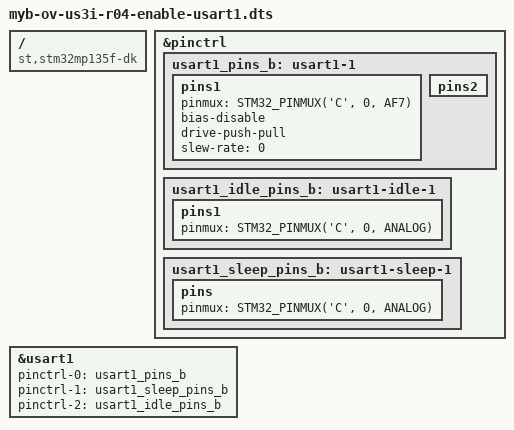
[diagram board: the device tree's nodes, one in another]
/dts-v1/;
/plugin/;

#include <dt-bindings/gpio/gpio.h>
#include <dt-bindings/pinctrl/stm32-pinfunc.h>

/ {
    compatible = "st,stm32mp135f-dk", "st,stm32mp135";

    fragment@0 {
        target = <&pinctrl>;
        __overlay__ {
            usart1_pins_b: usart1-1 {
                pins1 {
                    pinmux = <STM32_PINMUX('C', 0, AF7)>; /* USART1_TX */
                             /* <STM32_PINMUX('C', 2, AF7)>; USART1_RTS - Conflicts with ETH1_TXD2 (Row 58) */
                    bias-disable;
                    drive-push-pull;
                    slew-rate = <0>;
                };
                pins2 {
                    /* pinmux = <STM32_PINMUX('B', 0, AF4)>; USART1_RX - Conflicts with ETH1_RXD2 (Row 49) */
                    /* pinmux = <STM32_PINMUX('A', 7, AF7)>; USART1_CTS_NSS - Conflicts with ETH1_RXDV (Row 52) */
                    /* bias-pull-up; */
                };
            };

            usart1_idle_pins_b: usart1-idle-1 {
                pins1 {
                    pinmux = <STM32_PINMUX('C', 0, ANALOG)>; /* USART1_TX */
                    /* pinmux = <STM32_PINMUX('A', 7, ANALOG)>; USART1_CTS_NSS - Conflicts with ETH1_RXDV */
                };
                /* pins2 {
                    pinmux = <STM32_PINMUX('C', 2, AF7)>; USART1_RTS - Conflicts with ETH1_TXD2
                    bias-disable;
                    drive-push-pull;
                    slew-rate = <0>;
                };
                pins3 {
                    pinmux = <STM32_PINMUX('B', 0, AF4)>; USART1_RX - Conflicts with ETH1_RXD2
                    bias-pull-up;
                }; */
            };

            usart1_sleep_pins_b: usart1-sleep-1 {
                pins {
                    pinmux = <STM32_PINMUX('C', 0, ANALOG)>; /* USART1_TX */
                    /* <STM32_PINMUX('C', 2, ANALOG)>, USART1_RTS - Conflicts with ETH1_TXD2 */
                    /* <STM32_PINMUX('A', 7, ANALOG)>, USART1_CTS_NSS - Conflicts with ETH1_RXDV */
                    /* <STM32_PINMUX('B', 0, ANALOG)>; USART1_RX - Conflicts with ETH1_RXD2 */
                };
            };
        };
    };

    fragment@1 {
        target = <&usart1>;
        __overlay__ {
            pinctrl-names = "default", "sleep", "idle";
            pinctrl-0 = <&usart1_pins_b>;
            pinctrl-1 = <&usart1_sleep_pins_b>;
            pinctrl-2 = <&usart1_idle_pins_b>;
            status = "okay";
        };
    };
};
